AUTOSAR XML (schema 00044)
package /E40_Platform_System_SystemPackage/Components
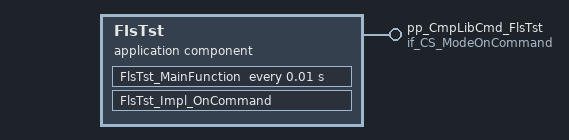
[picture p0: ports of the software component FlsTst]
  application sw component type FlsTst
    provide port pp_CmpLibCmd_FlsTst: server-com-spec{operation=Impl_OnCommand, queue-length=1}, provided-interface=if_CS_ModeOnCommand
    behavior IB_FlsTst: port-api-option{enable-take-address=false, indirect-api=false, port=pp_CmpLibCmd_FlsTst}
      operation invoked event OIE_pp_CmpLibCmd_FlsTst_FlsTst_Impl_OnCommandTrigByImpl_OnCommand: start-on-event=FlsTst_Impl_OnCommand, operation=pp_CmpLibCmd_FlsTst.Impl_OnCommand
      timing event TEFlsTst_MainFunction: start-on-event=FlsTst_MainFunction, period=0.01
      runnable FlsTst_Impl_OnCommand: can-be-invoked-concurrently=true
      runnable FlsTst_MainFunction: can-be-invoked-concurrently=true
  swc implementation IMPL_FlsTst: behavior=IB_FlsTst
